AUTOSAR XML (schema 4-0-3)
package /ComponentTypes
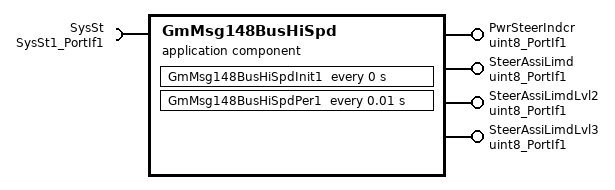
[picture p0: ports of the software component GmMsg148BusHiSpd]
  application sw component type GmMsg148BusHiSpd
    4 x provide port, all with nonqueued-sender-com-spec{data-element=Val, init-value=0}, provided-interface=uint8_PortIf1:
      PwrSteerIndcr
      SteerAssiLimd
      SteerAssiLimdLvl2
      SteerAssiLimdLvl3
    require port SysSt: nonqueued-receiver-com-spec{data-element=Val, filter=data-filter-type=ALWAYS, init-value=3}, required-interface=SysSt1_PortIf1
    behavior GmMsg148BusHiSpd_InternalBehavior: data-type-mapping=Nexteer
      timing event GmMsg148BusHiSpd_InitEvent: start-on-event=GmMsg148BusHiSpdInit1, period=0
      timing event TMT_GM0C9HSPer1: start-on-event=GmMsg148BusHiSpdPer1, period=0.01
      runnable GmMsg148BusHiSpdInit1
      runnable GmMsg148BusHiSpdPer1
        data-receive-point-by-arguments:
          access REC_SysSt_Val: accessed-variable=SysSt.Val
        data-send-points:
          4 x access:
            SEND_PwrSteerIndcr_Val: accessed-variable=PwrSteerIndcr.Val
            SEND_SteerAssiLimd_Val: accessed-variable=SteerAssiLimd.Val
            SEND_SteerAssiLimdLvl2_Val: accessed-variable=SteerAssiLimdLvl2.Val
            SEND_SteerAssiLimdLvl3_Val: accessed-variable=SteerAssiLimdLvl3.Val
  swc implementation GmMsg148BusHiSpd_Implementation: behavior=GmMsg148BusHiSpd_InternalBehavior
    code-descriptors:
      code Default: artifact-descriptors=autosar-engineering-object={short-label=Default, category=SWSRC}
